# fcr_me55 register map
Registers are read-write, no defined reset value unless marked. A register's access mark holds for its fields unless they carry their own. Offsets are from the block's base; lines under a group give offsets from that group; [hi:lo] are bit positions; {n}, {i} and the like mark numbered series; 'fields as' and 'values as' point back to an identical list; <NAME> marks a mode.

## Memory map
0x40000800 FCR size 0x400 — Function Control Register.

## FCR — Function Control Register.
Base 0x40000800
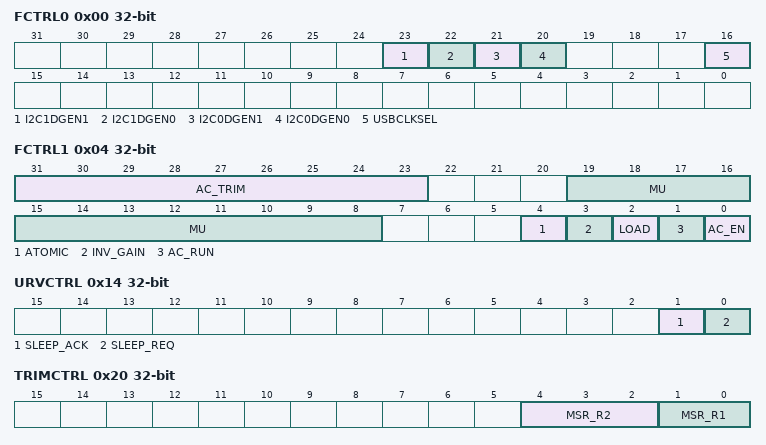
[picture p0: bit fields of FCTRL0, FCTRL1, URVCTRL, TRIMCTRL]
0x00 FCTRL0 — Register 0.
  [23] I2C1DGEN1 — I2C1 SCL Glitch Filter Enable.
    0=dis (Filter disabled.); 1=en (Filter enabled.)
  [22] I2C1DGEN0 — I2C1 SDA Glitch Filter Enable.
    0=dis (Filter disabled.); 1=en (Filter enabled.)
  [21] I2C0DGEN1 — I2C0 SCL Glitch Filter Enable.
    0=dis (Filter disabled.); 1=en (Filter enabled.)
  [20] I2C0DGEN0 — I2C0 SDA Glitch Filter Enable.
    0=dis (Filter disabled.); 1=en (Filter enabled.)
  [16] USBCLKSEL — USB External Core Clock Select.
    0=sys (Generated clock from system clock.); 1=dig (Digital clock from a GPIO.)
0x04 FCTRL1 — Register 1.
  [31:23] AC_TRIM — 150MHz HFIO Auto Calibration Trim
  [19:8] MU — MU value.
  [4] ATOMIC — Atomic mode.
    0=not (Not Running.); 1=run (Running.)
  [3] INV_GAIN — Invert Gain.
    0=not (Not Running.); 1=run (Running.)
  [2] LOAD — Load Trim.
  [1] AC_RUN — Autocalibration Run.
    0=not (Not Running.); 1=run (Running.)
  [0] AC_EN — Auto-calibration Enable.
    0=dis (Disabled.); 1=en (Enabled.)
0x0C FCTRL3 — Register 3.
  [7:0] DONECNT — Auto-calibration Done Counter Setting.
0x10 URVBOOTADDR — Register 4.
  [31:0] BOOTADDR — RISCV Boot Address.
0x14 URVCTRL — Register 5.
  [1] SLEEP_ACK — Acknowledgement of Sleep Request for RISCV.
  [0] SLEEP_REQ — Sleep Request to RISCV.
0x1C GP — General Purpose Register.
  [31:0] GP — General Purpose.
0x20 TRIMCTRL — MSR ADC Trim Register.
  [4:2] MSR_R2
    0=OPEN (Open drain.); 4=3K (3kOhm); 5=6K (6kOhm); 6=12K (12kOhm); 7=24K (24kOhm)
  [1:0] MSR_R1
    0=0K (0kOhm); 1=1P2K (1.2kOhm); 2=2P4K (2.4kOhm); 3=4P8K (4.8kOhm)
0x24 ERFOKS — ERFO Kick Start Register.
  [15:0] CTRL — Kick Start Control.
